# UFS0_UFSHCI2P1SS_16FFC_HCLK_ECC_AGGR_HCLK_ECC_AGGR_CFG register map
Vendor: Texas Instruments
Peripheral module from a debugger description file (folder J7_AHP).
Registers are 32-bit, access not given, reset 0x0 unless marked. A register's access mark holds for its fields unless they carry their own. Offsets are as the file gives them; lines under a group give offsets from that group; [hi:lo] are bit positions; {n}, {i} and the like mark numbered series; 'fields as' and 'values as' point back to an identical list; <NAME> marks a mode.

## UFS0_UFSHCI2P1SS_16FFC_HCLK_ECC_AGGR_HCLK_ECC_AGGR_CFG
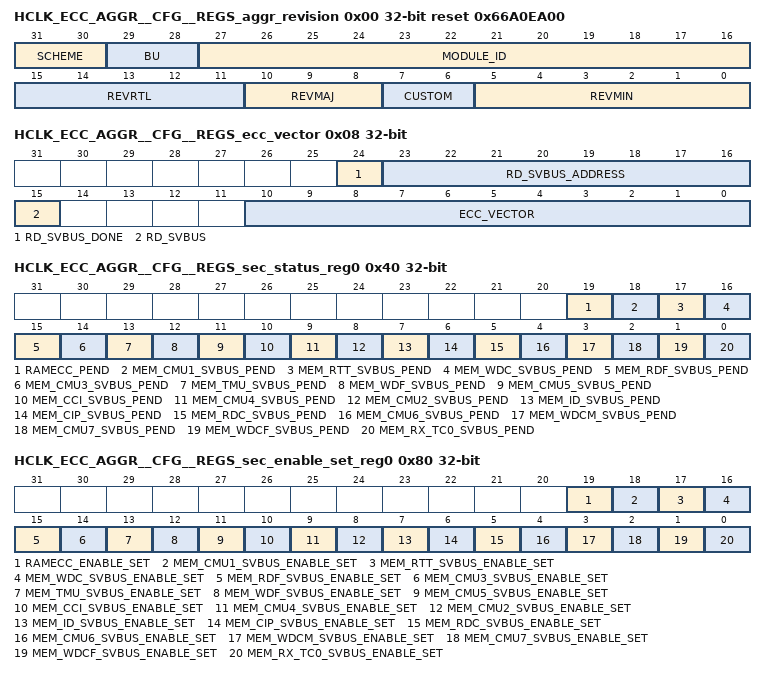
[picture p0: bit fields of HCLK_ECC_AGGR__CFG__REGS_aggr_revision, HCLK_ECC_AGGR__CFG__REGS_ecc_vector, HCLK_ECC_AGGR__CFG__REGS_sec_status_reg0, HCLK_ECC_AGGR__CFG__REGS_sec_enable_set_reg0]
0x00 HCLK_ECC_AGGR__CFG__REGS_aggr_revision ro reset 0x66A0EA00
  [31:30] SCHEME
  [29:28] BU
  [27:16] MODULE_ID
  [15:11] REVRTL — RTL version
  [10:8] REVMAJ — Major version
  [7:6] CUSTOM — Custom version
  [5:0] REVMIN — Minor version
0x08 HCLK_ECC_AGGR__CFG__REGS_ecc_vector
  [24] RD_SVBUS_DONE — Status to indicate if read on serial VBUS is complete, write of any value will clear this bit. (access R/W1TC)
  [23:16] RD_SVBUS_ADDRESS rw — Read address
  [15] RD_SVBUS — Write 1 to trigger a read on the serial VBUS (access R/W1TS)
  [10:0] ECC_VECTOR rw — Value written to select the corresponding ECC RAM for control or status
0x0C HCLK_ECC_AGGR__CFG__REGS_misc_status ro reset 0x14
  [10:0] NUM_RAMS — Indicates the number of RAMS serviced by the ECC aggregator
0x10 HCLK_ECC_AGGR__CFG__REGS_reserved_svbus rw
  [31:0] DATA — Serial VBUS register data
0x3C HCLK_ECC_AGGR__CFG__REGS_sec_eoi_reg
  [0] EOI_WR — EOI Register (access R/W1TS)
0x40 HCLK_ECC_AGGR__CFG__REGS_sec_status_reg0
  [19] RAMECC_PEND — Interrupt Pending Status for ramecc_pend (access R/W1TS)
  [18] MEM_CMU1_SVBUS_PEND — Interrupt Pending Status for mem_cmu1_svbus_pend (access R/W1TS)
  [17] MEM_RTT_SVBUS_PEND — Interrupt Pending Status for mem_rtt_svbus_pend (access R/W1TS)
  [16] MEM_WDC_SVBUS_PEND — Interrupt Pending Status for mem_wdc_svbus_pend (access R/W1TS)
  [15] MEM_RDF_SVBUS_PEND — Interrupt Pending Status for mem_rdf_svbus_pend (access R/W1TS)
  [14] MEM_CMU3_SVBUS_PEND — Interrupt Pending Status for mem_cmu3_svbus_pend (access R/W1TS)
  [13] MEM_TMU_SVBUS_PEND — Interrupt Pending Status for mem_tmu_svbus_pend (access R/W1TS)
  [12] MEM_WDF_SVBUS_PEND — Interrupt Pending Status for mem_wdf_svbus_pend (access R/W1TS)
  [11] MEM_CMU5_SVBUS_PEND — Interrupt Pending Status for mem_cmu5_svbus_pend (access R/W1TS)
  [10] MEM_CCI_SVBUS_PEND — Interrupt Pending Status for mem_cci_svbus_pend (access R/W1TS)
  [9] MEM_CMU4_SVBUS_PEND — Interrupt Pending Status for mem_cmu4_svbus_pend (access R/W1TS)
  [8] MEM_CMU2_SVBUS_PEND — Interrupt Pending Status for mem_cmu2_svbus_pend (access R/W1TS)
  [7] MEM_ID_SVBUS_PEND — Interrupt Pending Status for mem_id_svbus_pend (access R/W1TS)
  [6] MEM_CIP_SVBUS_PEND — Interrupt Pending Status for mem_cip_svbus_pend (access R/W1TS)
  [5] MEM_RDC_SVBUS_PEND — Interrupt Pending Status for mem_rdc_svbus_pend (access R/W1TS)
  [4] MEM_CMU6_SVBUS_PEND — Interrupt Pending Status for mem_cmu6_svbus_pend (access R/W1TS)
  [3] MEM_WDCM_SVBUS_PEND — Interrupt Pending Status for mem_wdcm_svbus_pend (access R/W1TS)
  [2] MEM_CMU7_SVBUS_PEND — Interrupt Pending Status for mem_cmu7_svbus_pend (access R/W1TS)
  [1] MEM_WDCF_SVBUS_PEND — Interrupt Pending Status for mem_wdcf_svbus_pend (access R/W1TS)
  [0] MEM_RX_TC0_SVBUS_PEND — Interrupt Pending Status for mem_rx_tc0_svbus_pend (access R/W1TS)
0x80 HCLK_ECC_AGGR__CFG__REGS_sec_enable_set_reg0
  [19] RAMECC_ENABLE_SET — Interrupt Enable Set Register for ramecc_pend (access R/W1TS)
  [18] MEM_CMU1_SVBUS_ENABLE_SET — Interrupt Enable Set Register for mem_cmu1_svbus_pend (access R/W1TS)
  [17] MEM_RTT_SVBUS_ENABLE_SET — Interrupt Enable Set Register for mem_rtt_svbus_pend (access R/W1TS)
  [16] MEM_WDC_SVBUS_ENABLE_SET — Interrupt Enable Set Register for mem_wdc_svbus_pend (access R/W1TS)
  [15] MEM_RDF_SVBUS_ENABLE_SET — Interrupt Enable Set Register for mem_rdf_svbus_pend (access R/W1TS)
  [14] MEM_CMU3_SVBUS_ENABLE_SET — Interrupt Enable Set Register for mem_cmu3_svbus_pend (access R/W1TS)
  [13] MEM_TMU_SVBUS_ENABLE_SET — Interrupt Enable Set Register for mem_tmu_svbus_pend (access R/W1TS)
  [12] MEM_WDF_SVBUS_ENABLE_SET — Interrupt Enable Set Register for mem_wdf_svbus_pend (access R/W1TS)
  [11] MEM_CMU5_SVBUS_ENABLE_SET — Interrupt Enable Set Register for mem_cmu5_svbus_pend (access R/W1TS)
  [10] MEM_CCI_SVBUS_ENABLE_SET — Interrupt Enable Set Register for mem_cci_svbus_pend (access R/W1TS)
  [9] MEM_CMU4_SVBUS_ENABLE_SET — Interrupt Enable Set Register for mem_cmu4_svbus_pend (access R/W1TS)
  [8] MEM_CMU2_SVBUS_ENABLE_SET — Interrupt Enable Set Register for mem_cmu2_svbus_pend (access R/W1TS)
  [7] MEM_ID_SVBUS_ENABLE_SET — Interrupt Enable Set Register for mem_id_svbus_pend (access R/W1TS)
  [6] MEM_CIP_SVBUS_ENABLE_SET — Interrupt Enable Set Register for mem_cip_svbus_pend (access R/W1TS)
  [5] MEM_RDC_SVBUS_ENABLE_SET — Interrupt Enable Set Register for mem_rdc_svbus_pend (access R/W1TS)
  [4] MEM_CMU6_SVBUS_ENABLE_SET — Interrupt Enable Set Register for mem_cmu6_svbus_pend (access R/W1TS)
  [3] MEM_WDCM_SVBUS_ENABLE_SET — Interrupt Enable Set Register for mem_wdcm_svbus_pend (access R/W1TS)
  [2] MEM_CMU7_SVBUS_ENABLE_SET — Interrupt Enable Set Register for mem_cmu7_svbus_pend (access R/W1TS)
  [1] MEM_WDCF_SVBUS_ENABLE_SET — Interrupt Enable Set Register for mem_wdcf_svbus_pend (access R/W1TS)
  [0] MEM_RX_TC0_SVBUS_ENABLE_SET — Interrupt Enable Set Register for mem_rx_tc0_svbus_pend (access R/W1TS)
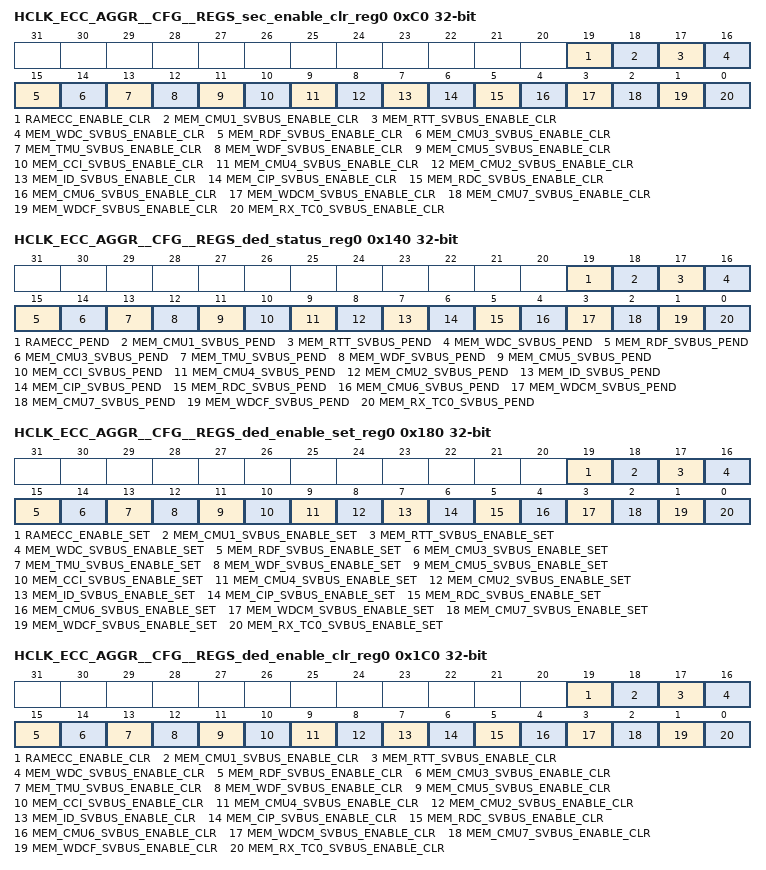
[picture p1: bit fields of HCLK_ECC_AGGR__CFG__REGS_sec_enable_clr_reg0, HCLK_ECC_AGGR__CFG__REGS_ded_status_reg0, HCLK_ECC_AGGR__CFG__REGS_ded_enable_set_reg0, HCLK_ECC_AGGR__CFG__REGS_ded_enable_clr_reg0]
0xC0 HCLK_ECC_AGGR__CFG__REGS_sec_enable_clr_reg0
  [19] RAMECC_ENABLE_CLR — Interrupt Enable Clear Register for ramecc_pend (access R/W1TC)
  [18] MEM_CMU1_SVBUS_ENABLE_CLR — Interrupt Enable Clear Register for mem_cmu1_svbus_pend (access R/W1TC)
  [17] MEM_RTT_SVBUS_ENABLE_CLR — Interrupt Enable Clear Register for mem_rtt_svbus_pend (access R/W1TC)
  [16] MEM_WDC_SVBUS_ENABLE_CLR — Interrupt Enable Clear Register for mem_wdc_svbus_pend (access R/W1TC)
  [15] MEM_RDF_SVBUS_ENABLE_CLR — Interrupt Enable Clear Register for mem_rdf_svbus_pend (access R/W1TC)
  [14] MEM_CMU3_SVBUS_ENABLE_CLR — Interrupt Enable Clear Register for mem_cmu3_svbus_pend (access R/W1TC)
  [13] MEM_TMU_SVBUS_ENABLE_CLR — Interrupt Enable Clear Register for mem_tmu_svbus_pend (access R/W1TC)
  [12] MEM_WDF_SVBUS_ENABLE_CLR — Interrupt Enable Clear Register for mem_wdf_svbus_pend (access R/W1TC)
  [11] MEM_CMU5_SVBUS_ENABLE_CLR — Interrupt Enable Clear Register for mem_cmu5_svbus_pend (access R/W1TC)
  [10] MEM_CCI_SVBUS_ENABLE_CLR — Interrupt Enable Clear Register for mem_cci_svbus_pend (access R/W1TC)
  [9] MEM_CMU4_SVBUS_ENABLE_CLR — Interrupt Enable Clear Register for mem_cmu4_svbus_pend (access R/W1TC)
  [8] MEM_CMU2_SVBUS_ENABLE_CLR — Interrupt Enable Clear Register for mem_cmu2_svbus_pend (access R/W1TC)
  [7] MEM_ID_SVBUS_ENABLE_CLR — Interrupt Enable Clear Register for mem_id_svbus_pend (access R/W1TC)
  [6] MEM_CIP_SVBUS_ENABLE_CLR — Interrupt Enable Clear Register for mem_cip_svbus_pend (access R/W1TC)
  [5] MEM_RDC_SVBUS_ENABLE_CLR — Interrupt Enable Clear Register for mem_rdc_svbus_pend (access R/W1TC)
  [4] MEM_CMU6_SVBUS_ENABLE_CLR — Interrupt Enable Clear Register for mem_cmu6_svbus_pend (access R/W1TC)
  [3] MEM_WDCM_SVBUS_ENABLE_CLR — Interrupt Enable Clear Register for mem_wdcm_svbus_pend (access R/W1TC)
  [2] MEM_CMU7_SVBUS_ENABLE_CLR — Interrupt Enable Clear Register for mem_cmu7_svbus_pend (access R/W1TC)
  [1] MEM_WDCF_SVBUS_ENABLE_CLR — Interrupt Enable Clear Register for mem_wdcf_svbus_pend (access R/W1TC)
  [0] MEM_RX_TC0_SVBUS_ENABLE_CLR — Interrupt Enable Clear Register for mem_rx_tc0_svbus_pend (access R/W1TC)
0x13C HCLK_ECC_AGGR__CFG__REGS_ded_eoi_reg
  [0] EOI_WR — EOI Register (access R/W1TS)
0x140 HCLK_ECC_AGGR__CFG__REGS_ded_status_reg0
  fields as HCLK_ECC_AGGR__CFG__REGS_sec_status_reg0
0x180 HCLK_ECC_AGGR__CFG__REGS_ded_enable_set_reg0
  fields as HCLK_ECC_AGGR__CFG__REGS_sec_enable_set_reg0
0x1C0 HCLK_ECC_AGGR__CFG__REGS_ded_enable_clr_reg0
  fields as HCLK_ECC_AGGR__CFG__REGS_sec_enable_clr_reg0
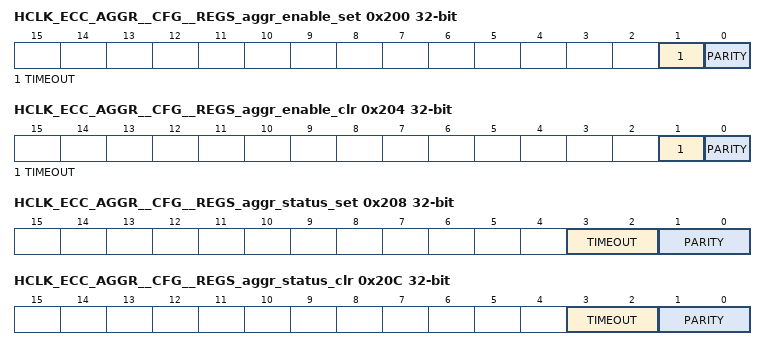
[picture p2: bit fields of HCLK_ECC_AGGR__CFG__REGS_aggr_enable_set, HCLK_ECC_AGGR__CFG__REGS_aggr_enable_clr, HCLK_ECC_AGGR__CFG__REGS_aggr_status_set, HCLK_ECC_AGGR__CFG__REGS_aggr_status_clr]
0x200 HCLK_ECC_AGGR__CFG__REGS_aggr_enable_set
  [1] TIMEOUT — interrupt enable set for svbus timeout errors (access R/W1TS)
  [0] PARITY — interrupt enable set for parity errors (access R/W1TS)
0x204 HCLK_ECC_AGGR__CFG__REGS_aggr_enable_clr
  [1] TIMEOUT — interrupt enable clear for svbus timeout errors (access R/W1TC)
  [0] PARITY — interrupt enable clear for parity errors (access R/W1TC)
0x208 HCLK_ECC_AGGR__CFG__REGS_aggr_status_set
  [3:2] TIMEOUT — interrupt status set for svbus timeout errors (access R/WI)
  [1:0] PARITY — interrupt status set for parity errors (access R/WI)
0x20C HCLK_ECC_AGGR__CFG__REGS_aggr_status_clr
  [3:2] TIMEOUT — interrupt status clear for svbus timeout errors (access R/WD)
  [1:0] PARITY — interrupt status clear for parity errors (access R/WD)
